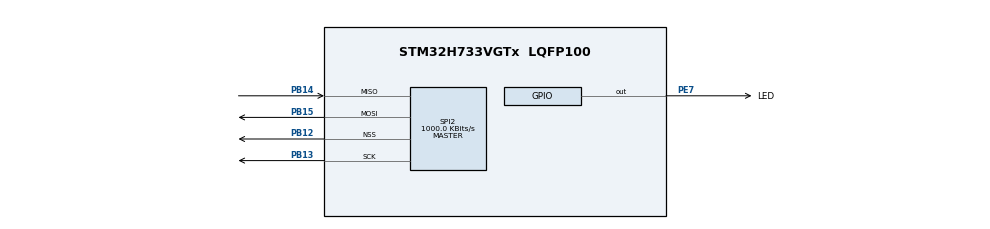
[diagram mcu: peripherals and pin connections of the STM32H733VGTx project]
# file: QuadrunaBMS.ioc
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Mcu.Family=STM32H7
Mcu.Name=STM32H733VGTx
Mcu.Package=LQFP100
NVIC.PriorityGroup=NVIC_PRIORITYGROUP_4
PA13(JTMS/SWDIO).Mode=Trace_Asynchronous_SW
PA13(JTMS/SWDIO).Signal=DEBUG_JTMS-SWDIO
PA14(JTCK/SWCLK).Mode=Trace_Asynchronous_SW
PA14(JTCK/SWCLK).Signal=DEBUG_JTCK-SWCLK
PB12.Mode=NSS_Signal_Hard_Output
PB12.Signal=SPI2_NSS
PB13.Mode=Full_Duplex_Master
PB13.Signal=SPI2_SCK
PB14.Mode=Full_Duplex_Master
PB14.Signal=SPI2_MISO
PB15.Mode=Full_Duplex_Master
PB15.Signal=SPI2_MOSI
PB3(JTDO/TRACESWO).Mode=Trace_Asynchronous_SW
PB3(JTDO/TRACESWO).Signal=DEBUG_JTDO-SWO
PE7.GPIO_Label=LED
PE7.Signal=GPIO_Output
PH0-OSC_IN.Mode=HSE-External-Oscillator
PH0-OSC_IN.Signal=RCC_OSC_IN
PH1-OSC_OUT.Mode=HSE-External-Oscillator
PH1-OSC_OUT.Signal=RCC_OSC_OUT
ProjectManager.HeapSize=0x200
ProjectManager.StackSize=0x400
ProjectManager.TargetToolchain=STM32CubeIDE
RCC.ADCFreq_Value=64000000
RCC.APB1Freq_Value=128000000
RCC.APB2Freq_Value=128000000
RCC.APB3Freq_Value=128000000
RCC.APB4Freq_Value=128000000
RCC.CortexFreq_Value=512000000
RCC.D1PPRE=RCC_APB3_DIV2
RCC.D2PPRE1=RCC_APB1_DIV2
RCC.D2PPRE2=RCC_APB2_DIV2
RCC.D3PPRE=RCC_APB4_DIV2
RCC.DIVM1=1
RCC.DIVM2=1
RCC.DIVN1=64
RCC.DIVN2=24
RCC.DIVP1=1
RCC.DIVP2=3
RCC.DIVQ1=4
RCC.HCLKFreq_Value=256000000
RCC.HPRE=RCC_HCLK_DIV2
RCC.HSE_VALUE=8000000
RCC.PLL2FRACN=0
RCC.PLL3FRACN=0
RCC.PLLFRACN=0
RCC.PLLSourceVirtual=RCC_PLLSOURCE_HSE
RCC.SPI123CLockSelection=RCC_SPI123CLKSOURCE_PLL2
RCC.SYSCLKFreq_VALUE=512000000
RCC.SYSCLKSource=RCC_SYSCLKSOURCE_PLLCLK
RCC.USBFreq_Value=128000000
SPI2.BaudRatePrescaler=SPI_BAUDRATEPRESCALER_64
SPI2.CLKPhase=SPI_PHASE_2EDGE
SPI2.CLKPolarity=SPI_POLARITY_HIGH
SPI2.CalculateBaudRate=1000.0 KBits/s
SPI2.DataSize=SPI_DATASIZE_8BIT
SPI2.Direction=SPI_DIRECTION_2LINES
SPI2.MasterKeepIOState=SPI_MASTER_KEEP_IO_STATE_ENABLE
SPI2.Mode=SPI_MODE_MASTER
SPI2.NSSPMode=SPI_NSS_PULSE_DISABLE
SPI2.VirtualNSS=VM_NSSHARD
SPI2.VirtualType=VM_MASTER
board=custom

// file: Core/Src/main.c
/* USER CODE BEGIN Header */
/**
  ******************************************************************************
  * @file           : main.c
  * @brief          : Main program body
  ******************************************************************************
  * @attention
  *
  * Copyright (c) 2024 STMicroelectronics.
  * All rights reserved.
  *
  * This software is licensed under terms that can be found in the LICENSE file
  * in the root directory of this software component.
  * If no LICENSE file comes with this software, it is provided AS-IS.
  *
  ******************************************************************************
  */
/* USER CODE END Header */
#include "main.h"

/* USER CODE BEGIN Includes */

#include <stdio.h>

/* USER CODE END Includes */

SPI_HandleTypeDef hspi2;

void SystemClock_Config(void);
static void MX_GPIO_Init(void);
static void MX_SPI2_Init(void);

int main(void)
{

  /* USER CODE BEGIN 1 */

	uint8_t dataToSend = 2;

  /* USER CODE END 1 */

  /* MCU Configuration--------------------------------------------------------*/

  /* Reset of all peripherals, Initializes the Flash interface and the Systick. */
  HAL_Init();

  /* Configure the system clock */
  SystemClock_Config();

  /* Initialize all configured peripherals */
  MX_GPIO_Init();
  MX_SPI2_Init();

  /* Infinite loop */
  /* USER CODE BEGIN WHILE */
  while (1)
  {

	  HAL_SPI_Transmit(&hspi2, &dataToSend, 1, 100);
	  HAL_Delay(500);

//	  // Wait for data to be received
//	  while (__HAL_SPI_GET_FLAG(&hspi2, SPI_FLAG_RXNE) == RESET);
//
//	  // Read the received data
//	  uint8_t receivedData;
//	  HAL_SPI_Receive(&hspi2, &receivedData, 1, HAL_MAX_DELAY);
//
//	  // Process received data, in this case, just print it
//	  printf("Received: %d\n", receivedData);

    /* USER CODE END WHILE */

  }
}

void SystemClock_Config(void)
{
  RCC_OscInitTypeDef RCC_OscInitStruct = {0};
  RCC_ClkInitTypeDef RCC_ClkInitStruct = {0};

  /** Supply configuration update enable
  */
  HAL_PWREx_ConfigSupply(PWR_LDO_SUPPLY);

  /** Configure the main internal regulator output voltage
  */
  __HAL_PWR_VOLTAGESCALING_CONFIG(PWR_REGULATOR_VOLTAGE_SCALE0);

  while(!__HAL_PWR_GET_FLAG(PWR_FLAG_VOSRDY)) {}

  /** Initializes the RCC Oscillators according to the specified parameters
  * in the RCC_OscInitTypeDef structure.
  */
  RCC_OscInitStruct.OscillatorType = RCC_OSCILLATORTYPE_HSE;
  RCC_OscInitStruct.HSEState = RCC_HSE_ON;
  RCC_OscInitStruct.PLL.PLLState = RCC_PLL_ON;
  RCC_OscInitStruct.PLL.PLLSource = RCC_PLLSOURCE_HSE;
  RCC_OscInitStruct.PLL.PLLM = 1;
  RCC_OscInitStruct.PLL.PLLN = 64;
  RCC_OscInitStruct.PLL.PLLP = 1;
  RCC_OscInitStruct.PLL.PLLQ = 4;
  RCC_OscInitStruct.PLL.PLLR = 2;
  RCC_OscInitStruct.PLL.PLLRGE = RCC_PLL1VCIRANGE_3;
  RCC_OscInitStruct.PLL.PLLVCOSEL = RCC_PLL1VCOWIDE;
  RCC_OscInitStruct.PLL.PLLFRACN = 0;
  if (HAL_RCC_OscConfig(&RCC_OscInitStruct) != HAL_OK)
  {
    Error_Handler();
  }

  /** Initializes the CPU, AHB and APB buses clocks
  */
  RCC_ClkInitStruct.ClockType = RCC_CLOCKTYPE_HCLK|RCC_CLOCKTYPE_SYSCLK
                              |RCC_CLOCKTYPE_PCLK1|RCC_CLOCKTYPE_PCLK2
                              |RCC_CLOCKTYPE_D3PCLK1|RCC_CLOCKTYPE_D1PCLK1;
  RCC_ClkInitStruct.SYSCLKSource = RCC_SYSCLKSOURCE_PLLCLK;
  RCC_ClkInitStruct.SYSCLKDivider = RCC_SYSCLK_DIV1;
  RCC_ClkInitStruct.AHBCLKDivider = RCC_HCLK_DIV2;
  RCC_ClkInitStruct.APB3CLKDivider = RCC_APB3_DIV2;
  RCC_ClkInitStruct.APB1CLKDivider = RCC_APB1_DIV2;
  RCC_ClkInitStruct.APB2CLKDivider = RCC_APB2_DIV2;
  RCC_ClkInitStruct.APB4CLKDivider = RCC_APB4_DIV2;

  if (HAL_RCC_ClockConfig(&RCC_ClkInitStruct, FLASH_LATENCY_3) != HAL_OK)
  {
    Error_Handler();
  }
}

static void MX_SPI2_Init(void)
{

  /* SPI2 parameter configuration*/
  hspi2.Instance = SPI2;
  hspi2.Init.Mode = SPI_MODE_MASTER;
  hspi2.Init.Direction = SPI_DIRECTION_2LINES;
  hspi2.Init.DataSize = SPI_DATASIZE_8BIT;
  hspi2.Init.CLKPolarity = SPI_POLARITY_HIGH;
  hspi2.Init.CLKPhase = SPI_PHASE_2EDGE;
  hspi2.Init.NSS = SPI_NSS_HARD_OUTPUT;
  hspi2.Init.BaudRatePrescaler = SPI_BAUDRATEPRESCALER_64;
  hspi2.Init.FirstBit = SPI_FIRSTBIT_MSB;
  hspi2.Init.TIMode = SPI_TIMODE_DISABLE;
  hspi2.Init.CRCCalculation = SPI_CRCCALCULATION_DISABLE;
  hspi2.Init.CRCPolynomial = 0x0;
  hspi2.Init.NSSPMode = SPI_NSS_PULSE_DISABLE;
  hspi2.Init.NSSPolarity = SPI_NSS_POLARITY_LOW;
  hspi2.Init.FifoThreshold = SPI_FIFO_THRESHOLD_01DATA;
  hspi2.Init.TxCRCInitializationPattern = SPI_CRC_INITIALIZATION_ALL_ZERO_PATTERN;
  hspi2.Init.RxCRCInitializationPattern = SPI_CRC_INITIALIZATION_ALL_ZERO_PATTERN;
  hspi2.Init.MasterSSIdleness = SPI_MASTER_SS_IDLENESS_00CYCLE;
  hspi2.Init.MasterInterDataIdleness = SPI_MASTER_INTERDATA_IDLENESS_00CYCLE;
  hspi2.Init.MasterReceiverAutoSusp = SPI_MASTER_RX_AUTOSUSP_DISABLE;
  hspi2.Init.MasterKeepIOState = SPI_MASTER_KEEP_IO_STATE_ENABLE;
  hspi2.Init.IOSwap = SPI_IO_SWAP_DISABLE;
  if (HAL_SPI_Init(&hspi2) != HAL_OK)
  {
    Error_Handler();
  }

}

static void MX_GPIO_Init(void)
{
  GPIO_InitTypeDef GPIO_InitStruct = {0};

  /* GPIO Ports Clock Enable */
  __HAL_RCC_GPIOH_CLK_ENABLE();
  __HAL_RCC_GPIOE_CLK_ENABLE();
  __HAL_RCC_GPIOB_CLK_ENABLE();
  __HAL_RCC_GPIOA_CLK_ENABLE();

  /*Configure GPIO pin Output Level */
  HAL_GPIO_WritePin(LED_GPIO_Port, LED_Pin, GPIO_PIN_RESET);

  /*Configure GPIO pin : LED_Pin */
  GPIO_InitStruct.Pin = LED_Pin;
  GPIO_InitStruct.Mode = GPIO_MODE_OUTPUT_PP;
  GPIO_InitStruct.Pull = GPIO_NOPULL;
  GPIO_InitStruct.Speed = GPIO_SPEED_FREQ_LOW;
  HAL_GPIO_Init(LED_GPIO_Port, &GPIO_InitStruct);

}

void Error_Handler(void)
{
  __disable_irq();
  while (1)
  {
  }
}
